# STM32WB1Mxx register map
File version: 1.0
Registers are 32-bit, read-write, reset 0x0 unless marked. A register's access mark holds for its fields unless they carry their own. Offsets are from the block's base; lines under a group give offsets from that group; [hi:lo] are bit positions; {n}, {i} and the like mark numbered series; 'fields as' and 'values as' point back to an identical list; <NAME> marks a mode.

## Memory map
0x40000000 TIM2 — TIM
0x40002800 RTC — Real-Time Clock
0x40002C00 WWDG — Window WATCHDOG
0x40003000 IWDG — Independent WATCHDOG
0x40005400 I2C1 — Inter-integrated Circuit Interface
0x40007C00 LPTIM1 — LPTIMER
0x40008000 LPUART1 — Universal Synchronous Asynchronous Receiver Transmitter
0x40009400 LPTIM2 — LPTIMER
0x40010000 SYSCFG — System configuration controller
0x40010200 COMP1 — Comparator
0x40012400 ADC1 — Analog to Digital Converter
0x40012C00 TIM1 — TIM
0x40013000 SPI1 — Serial Peripheral Interface
0x40013800 USART1 — Universal Synchronous Asynchronous Receiver Transmitter
0x40020000 DMA1
0x40020800 DMAMUX1 — DMA Multiplexer
0x40023000 CRC — CRC calculation unit
0x40024000 TSC — Touch Sensing Controller (TSC)
0x48000000 GPIOA — General Purpose I/O
0x48000400 GPIOB — General Purpose I/O
0x48000800 GPIOC — General Purpose I/O
0x48001000 GPIOE — General Purpose I/O
0x48001C00 GPIOH — General Purpose I/O
0x58000000 RCC — Reset and Clock Control
0x58000400 PWR — Power Control
0x58000800 EXTI — Async Interrupts and Events Controller
0x58000C00 IPCC — Inter-Processor Communication
0x58001000 RNG
0x58001400 HSEM — HW Semaphore HSEM
0x58001800 AES2 — AES hardware accelerator
0x58002000 PKA — Public Key Accelerator (PKA)
0x58004000 FLASH — FLASH Registers
0xE0042000 DBGMCU — Debug MCU

## Interrupts
0 WWDG — Window WatchDog Interrupt
3 RTC_WKUP (RTC) — RTC Wakeup Interrupt
4 FLASH — FLASH (CFI) global Interrupt
5 RCC — RCC Interrupt
6 EXTI0 (EXTI) — EXTI Line 0 Interrupt
7 EXTI1 (EXTI) — EXTI Line 1 Interrupt
8 EXTI2 (EXTI) — EXTI Line 2 Interrupt
9 EXTI3 (EXTI) — EXTI Line 3 Interrupt
10 EXTI4 (EXTI) — EXTI Line 4 Interrupt
11 DMA1_Channel1 (DMA1) — DMA1 Channel 1 Interrupt
12 DMA1_Channel2 (DMA1) — DMA1 Channel 2 Interrupt
13 DMA1_Channel3 (DMA1) — DMA1 Channel 3 Interrupt
14 DMA1_Channel4 (DMA1) — DMA1 Channel 4 Interrupt
15 DMA1_Channel5 (DMA1) — DMA1 Channel 5 Interrupt
16 DMA1_Channel6 (DMA1) — DMA1 Channel 6 Interrupt
17 DMA1_Channel7 (DMA1) — DMA1 Channel 7 Interrupt
18 ADC1 — ADC1 Interrupt
21 C2SEV_PWR_C2H (PWR) — CPU2 SEV Interrupt
22 COMP (COMP1) — COMP1 Interrupt
23 EXTI9_5 (EXTI) — EXTI Lines [9:5] Interrupt
24 TIM1_BRK (TIM1) — TIM1 Break Interrupt
25 TIM1_UP (TIM1) — TIM1 Update Interrupt
26 TIM1_TRG_COM (TIM1) — TIM1 Trigger and Communication Interrupts
27 TIM1_CC (TIM1) — TIM1 Capture Compare Interrupt
28 TIM2 — TIM2 Global Interrupt
29 PKA — PKA Interrupt
30 I2C1_EV (I2C1) — I2C1 Event Interrupt
31 I2C1_ER (I2C1) — I2C1 Error Interrupt
34 SPI1 — SPI1 Interrupt
36 USART1 — USART1 Interrupt
37 LPUART1 — LPUART1 Interrupt
39 TSC — TSC Interrupt
40 EXTI15_10 (EXTI) — EXTI Lines1[15:10 ]Interrupts
41 RTC_Alarm (RTC) — RTC Alarms (A and B) Interrupt
43 PWR_SOTF_BLEACT_RFPHASE (PWR)
44 IPCC_C1_RX (IPCC) — IPCC RX Occupied Interrupt
45 IPCC_C1_TX (IPCC) — IPCC TX Free Interrupt
46 HSEM — HSEM Interrupt
47 LPTIM1 — LPTIM1 Interrupt
48 LPTIM2 — LPTIM2 Interrupt
52 AES2 — AES2 Interrupt
53 RNG — RNG Interrupt
62 DMAMUX1_OVR (DMAMUX1) — DMAMUX1 overrun Interrupt

## WWDG — Window WATCHDOG
Base 0x40002C00
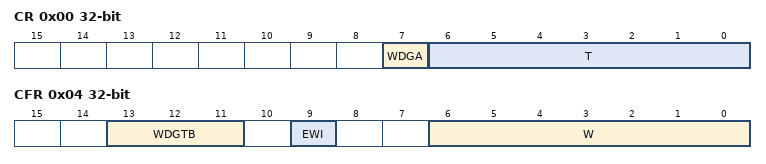
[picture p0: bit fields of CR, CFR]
0x00 CR — WWDG Control register
  [7] WDGA — Activation bit
  [6:0] T — T[6:0] bits (7-Bit counter (MSB to LSB))
0x04 CFR — WWDG Configuration register
  [13:11] WDGTB — WDGTB[2:0] bits (Timer Base)
    0=PRESCALER_1 (WWDG counter clock = (PCLK1/4096)/1); 1=PRESCALER_2 (WWDG counter clock = (PCLK1/4096)/2); 2=PRESCALER_4 (WWDG counter clock = (PCLK1/4096)/4); 3=PRESCALER_8 (WWDG counter clock = (PCLK1/4096)/8); 4=PRESCALER_16 (WWDG counter clock = (PCLK1/4096)/16); 5=PRESCALER_32 (WWDG counter clock = (PCLK1/4096)/32); 6=PRESCALER_64 (WWDG counter clock = (PCLK1/4096)/64); 7=PRESCALER_128 (WWDG counter clock = (PCLK1/4096)/128)
  [9] EWI — Early Wakeup Interrupt
  [6:0] W — W[6:0] bits (7-bit window value)
0x08 SR — WWDG Status register
  [0] EWIF — Early Wakeup Interrupt Flag
